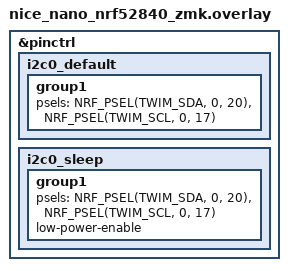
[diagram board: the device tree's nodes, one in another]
/*
 * OLED on the nice!nano's i2c0.
 *
 * The board's stock pinctrl is SDA = P0.17 (D2) and SCL = P0.20 (D3), but this
 * dongle is wired the other way round, so override both pinctrl states to match
 * the hardware: SDA = P0.20, SCL = P0.17. Nothing else on the dongle uses i2c0.
 *
 * If you ever rewire the display to the stock pin assignment, delete the
 * &pinctrl block below rather than editing the psels.
 */

#define DONGLE_OLED_I2C pro_micro_i2c

&pinctrl {
    i2c0_default: i2c0_default {
        group1 {
            psels = <NRF_PSEL(TWIM_SDA, 0, 20)>,
                <NRF_PSEL(TWIM_SCL, 0, 17)>;
        };
    };

    i2c0_sleep: i2c0_sleep {
        group1 {
            psels = <NRF_PSEL(TWIM_SDA, 0, 20)>,
                <NRF_PSEL(TWIM_SCL, 0, 17)>;
            low-power-enable;
        };
    };
};

#include "../dongle_oled.dtsi"
